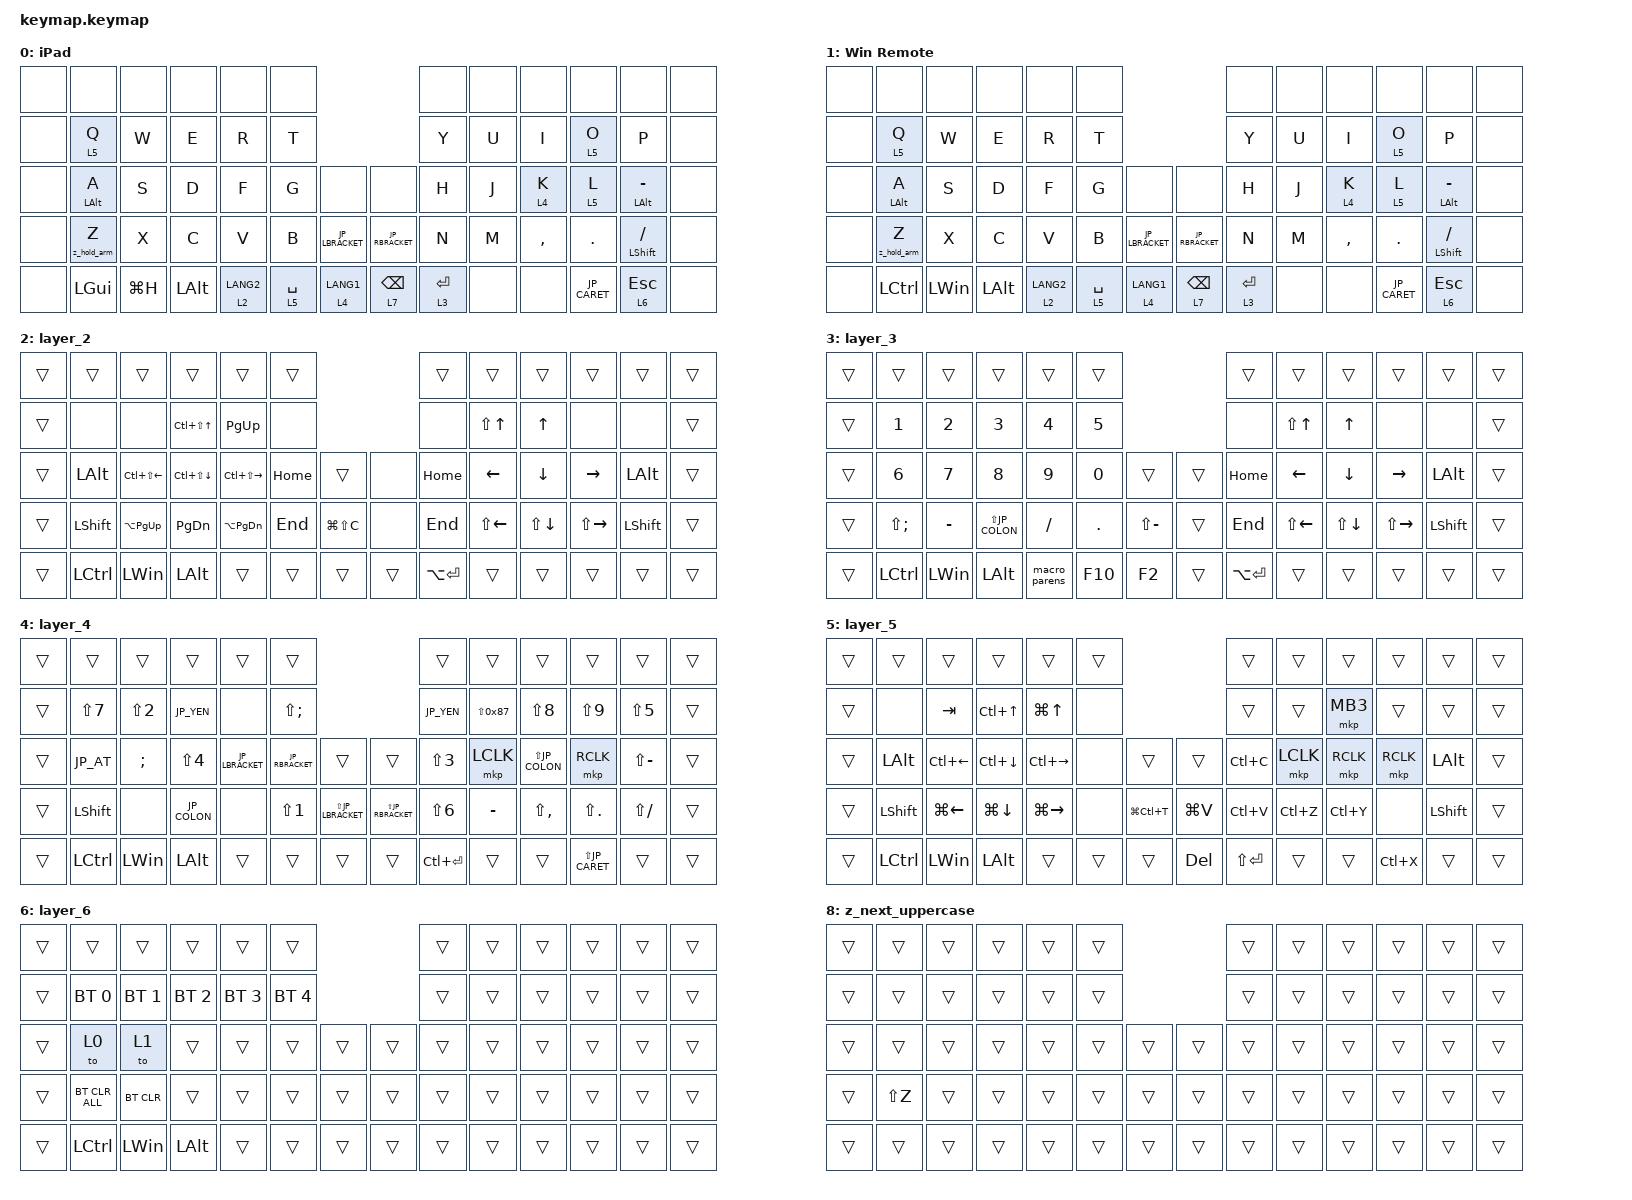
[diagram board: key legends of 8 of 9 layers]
#include <behaviors.dtsi>

&sl {
    release-after-ms = <300>;
};
#include <dt-bindings/zmk/bt.h>
#include <dt-bindings/zmk/keys.h>
#include <dt-bindings/zmk/outputs.h>
#include <dt-bindings/zmk/pointing.h>
#include <dt-bindings/zmk/input_transform.h>
#include <zephyr/dt-bindings/input/input-event-codes.h>
#include <scroll-snap.dtsi>

&mt {
    flavor = "balanced";
    quick-tap-ms = <0>;
};

// -------------------------------------------------------------------------
// JIS変換定義 (OSが日本語配列設定の場合の出力マッピング)
// -------------------------------------------------------------------------
#define JP_AT           LBKT             // @ (USの [ キー)
#define JP_CARET        EQUAL            // ^ (USの = キー)
#define JP_YEN          INT3             // ¥ (JISの ¥ キー)
#define JP_PIPE         LS(INT3)         // | (Shift + ¥)
#define JP_COLON        SQT              // : (USの ' キー)
#define JP_LBRACKET     RBKT             // [ (USの ] キー)
#define JP_RBRACKET     NUHS             // ] (USの \ キー / Non-US #)
#define JP_UNDERSCORE   LS(INT1)         // _ (Shift + Ro)
#define JP_BACKSLASH    INT1             // \ (Roキー)

// Shiftが必要な記号
#define JP_DQUOTE       LS(N2)           // "
#define JP_AMPERSAND    LS(N6)           // &
#define JP_QUOTE        LS(N7)           // '
#define JP_LPAREN       LS(N8)           // (
#define JP_RPAREN       LS(N9)           // )
#define JP_EQUAL        LS(MINUS)        // =
#define JP_PLUS         LS(SEMI)         // +
#define JP_ASTERISK     LS(SQT)          // *
#define JP_TILD         LS(EQUAL)        // ~
#define JP_GRAVE        LS(LBKT)         // `
#define JP_LBRACE       LS(RBKT)         // {
#define JP_RBRACE       LS(NUHS)         // }

/ {
    macros {
        // roBaと同じ: 長押し中はShift、離した直後だけ次のZを大文字にする。
        z_hold_arm: z_hold_arm {
            compatible = "zmk,behavior-macro";
            #binding-cells = <0>;
            wait-ms = <0>;
            tap-ms = <10>;
            bindings =
                <&macro_press &kp LSHFT>
                , <&macro_pause_for_release>
                , <&macro_release &kp LSHFT>
                , <&macro_tap &sl 8>;
        };

        // enダッシュ (Alt + 0150)
        en_dash: en_dash {
            compatible = "zmk,behavior-macro";
            #binding-cells = <0>;
            bindings
                = <&macro_press &kp LALT>
                , <&macro_tap &kp KP_N0 &kp KP_N1 &kp KP_N5 &kp KP_N0>
                , <&macro_release &kp LALT>;
        };

        // emダッシュ (Alt + 0151)
        em_dash: em_dash {
            compatible = "zmk,behavior-macro";
            #binding-cells = <0>;
            bindings
                = <&macro_press &kp LALT>
                , <&macro_tap &kp KP_N0 &kp KP_N1 &kp KP_N5 &kp KP_N1>
                , <&macro_release &kp LALT>;
        };

        // 数学マイナス記号 (Alt + 8722)
        math_minus: math_minus {
            compatible = "zmk,behavior-macro";
            #binding-cells = <0>;
            bindings
                = <&macro_press &kp LALT>
                , <&macro_tap &kp KP_N8 &kp KP_N7 &kp KP_N2 &kp KP_N2>
                , <&macro_release &kp LALT>;
        };
        
        macro_parens: macro_parens {
            compatible = "zmk,behavior-macro";
            #binding-cells = <0>;
            wait-ms = <20>; // キー入力間の待機時間
            tap-ms = <20>;  // キーを押している時間
            bindings
                = <&kp LS(N8)>    // 「(」を入力
                , <&kp LS(N9)>    // 「)」を入力
                , <&kp LEFT>;  // 左矢印「←」を入力してカーソルを戻す
        };

        // 単発・ホールド兼用のミドルクリックマクロ
        mclk_macro_hold: mclk_macro_hold {
            compatible = "zmk,behavior-macro";
            #binding-cells = <0>;
            wait-ms = <0>;
            tap-ms = <0>;
            bindings = <&macro_press &mkp MB3>
                     , <&macro_pause_for_release>
                     , <&macro_release &mkp MB3>;
        };

        // Ctrl＋ミドルクリックのホールド用マクロ
        ctrl_mclk_macro_hold: ctrl_mclk_macro_hold {
            compatible = "zmk,behavior-macro";
            #binding-cells = <0>;
            wait-ms = <0>;
            tap-ms = <0>;
            bindings = <&macro_press &kp LCTRL &mkp MB3>
                     , <&macro_pause_for_release>
                     , <&macro_release &kp LCTRL &mkp MB3>;
        };
    };

    behaviors {
        // Z: normal Japanese typing first; hold 170 ms = Shift.
        z_shift: z_shift {
            compatible = "zmk,behavior-hold-tap";
            label = "Z_SHIFT";
            #binding-cells = <2>;
            bindings = <&z_hold_arm>, <&kp>;
            flavor = "tap-preferred";
            tapping-term-ms = <170>;
            quick-tap-ms = <0>;
            require-prior-idle-ms = <125>;
        };

        // A: keep letter taps responsive, delay hold Alt to 320 ms.
        a_alt_slow: a_alt_slow {
            compatible = "zmk,behavior-hold-tap";
            #binding-cells = <2>;
            bindings = <&kp>, <&kp>;
            flavor = "tap-preferred";
            tapping-term-ms = <320>;
            quick-tap-ms = <150>;
            require-prior-idle-ms = <125>;
        };

        // 右Shift専用: 左Zと同じ170ms。通常のスラッシュ入力はタップ優先。
        slash_shift_fast: slash_shift_fast {
            compatible = "zmk,behavior-hold-tap";
            #binding-cells = <2>;
            bindings = <&kp>, <&kp>;
            flavor = "tap-preferred";
            tapping-term-ms = <170>;
            quick-tap-ms = <0>;
            require-prior-idle-ms = <125>;
        };

        // 高速タイピング用のMod-Tap設定（Home Row Mods用）
        mt_tap: mod_tap_preferred {
            compatible = "zmk,behavior-hold-tap";
            #binding-cells = <2>;
            flavor = "tap-preferred";      // ★重要：他のキーと重なってもTap（文字）を優先する
            tapping-term-ms = <200>;       // 長押しの判定時間（好みで調整）
            quick-tap-ms = <150>;          // 連続タップで文字をリピートさせる
            require-prior-idle-ms = <125>; // ★超重要：直前に別のキーを打っていたら、強制的にTapにする
            bindings = <&kp>, <&kp>;
        };
        
        // KとL専用の遅いLayer-Tap
        lt_slow: layer_tap_slow {
            compatible = "zmk,behavior-hold-tap";
            #binding-cells = <2>;
            flavor = "tap-preferred"; // 短く押した時は確実にキー入力を優先
            tapping-term-ms = <250>;  // ★ここを好みの長さに設定（デフォルトは200）
            quick-tap-ms = <200>;     // 連続タップ時のレイヤー暴発防止
            require-prior-idle-ms = <125>; // ★これを追加：直前に別のキー入力があれば絶対にTap(文字)にする
            bindings = <&mo>, <&kp>;  // 長押しでレイヤー(&mo)、短押しでキー(&kp)
            
            display-name = "Layer Tap Slow";
        };

        // ダブルタップ＆ホールドで連続バックスペースになるLayer-Tap
        lt_bspc: layer_tap_backspace {
            compatible = "zmk,behavior-hold-tap";
            #binding-cells = <2>;
            flavor = "tap-preferred";
            tapping-term-ms = <200>; // 通常の長押し（Hold）判定時間
            quick-tap-ms = <200>;    // ★ここがダブルタップリピートの受付時間です
            bindings = <&mo>, <&kp>; // ※もしMod-Tapとして使う場合は <&kp>, <&kp> にしてください
        };

        // ① カンマ用：ホールドでMB3、タップで通常のキー（bindingsを同一種にするためマクロでラップ）
        p_mt_mb3: p_mt_mb3 {
            compatible = "zmk,behavior-hold-tap";
            #binding-cells = <2>;
            flavor = "tap-preferred";
            tapping-term-ms = <200>;
            quick-tap-ms = <150>;
            require-prior-idle-ms = <125>;
            bindings = <&mclk_macro_hold>, <&kp>; // 両方とも「マクロ」として扱うことでエラーを回避
        };

        // ② ドット用：ホールドでCtrl+MB3、タップで通常のキー
        p_mt_ctrl_mb3: p_mt_ctrl_mb3 {
            compatible = "zmk,behavior-hold-tap";
            #binding-cells = <2>;
            flavor = "tap-preferred";
            tapping-term-ms = <200>;
            quick-tap-ms = <150>;
            require-prior-idle-ms = <125>;
            bindings = <&ctrl_mclk_macro_hold>, <&kp>; // 両方とも「マクロ」として扱う
        };
    };

    keymap {
        compatible = "zmk,keymap";

        mac_ipad {
            display-name = "iPad";
            bindings = <
&none      &none             &none         &none         &none       &none                                                      &none        &none  &none               &none                &none                &none
&none      &lt_slow 5 Q      &kp W         &kp E         &kp R       &kp T                                                      &kp Y        &kp U  &kp I               &lt_slow 5 O         &kp P                &none
&none      &a_alt_slow LALT A    &kp S         &kp D         &kp F       &kp G        &none                      &none              &kp H        &kp J  &lt_slow 4 K        &lt_slow 5 L         &a_alt_slow LALT MINUS   &none
&none      &z_shift 0 Z   &kp X         &kp C         &kp V       &kp B        &kp JP_LBRACKET            &kp JP_RBRACKET    &kp N        &kp M  &kp COMMA           &kp DOT              &slash_shift_fast LSHFT SLASH  &none
&none      &kp LGUI          &kp LG(H)      &kp LEFT_ALT  &lt 2 LANG2  &lt 5 SPACE  &lt 4 LANG1                 &lt_bspc 7 BSPC    &lt 3 RET    &none  &none               &kp JP_CARET         &lt 6 ESC            &none
            >;
        };

        win_remote {
            display-name = "Win Remote";
            bindings = <
&none      &none             &none         &none         &none       &none                                                      &none        &none  &none               &none                &none                &none
&none      &lt_slow 5 Q      &kp W         &kp E         &kp R       &kp T                                                      &kp Y        &kp U  &kp I               &lt_slow 5 O         &kp P                &none
&none      &a_alt_slow LALT A    &kp S         &kp D         &kp F       &kp G        &none                      &none              &kp H        &kp J  &lt_slow 4 K        &lt_slow 5 L         &a_alt_slow LALT MINUS   &none
&none      &z_shift 0 Z   &kp X         &kp C         &kp V       &kp B        &kp JP_LBRACKET            &kp JP_RBRACKET    &kp N        &kp M  &kp COMMA           &kp DOT              &slash_shift_fast LSHFT SLASH  &none
&none      &kp LCTRL         &kp LWIN      &kp LEFT_ALT  &lt 2 LANG2  &lt 5 SPACE  &lt 4 LANG1                 &lt_bspc 7 BSPC    &lt 3 RET    &none  &none               &kp JP_CARET         &lt 6 ESC            &none
            >;
        };

        layer_2 {
            bindings = <
&trans  &trans     &trans               &trans            &trans              &trans                            &trans          &trans           &trans            &trans         &trans    &trans
&trans  &none      &none                &kp LC(LS(UP))    &kp PG_UP           &none                             &none           &kp LS(UP)       &kp UP            &none          &none     &trans
&trans  &kp LALT   &kp LC(LS(LEFT))     &kp LC(LS(DOWN))  &kp LC(LS(RIGHT))   &kp HOME   &trans         &none   &kp HOME        &kp LEFT         &kp DOWN          &kp RIGHT      &kp LALT  &trans
&trans  &kp LSHFT  &kp LA(PG_UP)        &kp PG_DN         &kp LA(PG_DN)       &kp END    &kp LG(LS(C))  &none   &kp END         &kp LS(LEFT)     &kp LS(DOWN)      &kp LS(RIGHT)  &kp LSHFT &trans
&trans  &kp LCTRL  &kp LWIN             &kp LALT          &trans              &trans     &trans         &trans  &kp LA(ENTER)   &trans           &trans            &trans         &trans    &trans
            >;
        };

        layer_3 {
            bindings = <
&trans  &trans       &trans      &trans           &trans        &trans                          &trans        &trans           &trans            &trans         &trans       &trans
&trans  &kp N1       &kp N2      &kp N3           &kp N4        &kp N5                          &none         &kp LS(UP)       &kp UP            &none          &none        &trans
&trans  &kp N6       &kp N7      &kp N8           &kp N9        &kp N0   &trans         &trans  &kp HOME      &kp LEFT         &kp DOWN          &kp RIGHT      &kp LALT     &trans
&trans  &kp LS(SEMI) &kp MINUS   &kp LS(JP_COLON) &kp FSLH      &kp DOT  &kp LS(MINUS)  &trans  &kp END       &kp LS(LEFT)     &kp LS(DOWN)      &kp LS(RIGHT)  &kp LSHFT    &trans
&trans  &kp LCTRL    &kp LWIN    &kp LALT         &macro_parens &kp F10  &kp F2         &trans  &kp LA(ENTER) &trans           &trans            &trans         &trans       &trans
            >;
        };

        layer_4 {
            bindings = <
&trans  &trans        &trans        &trans        &trans          &trans                                                     &trans        &trans       &trans           &trans            &trans         &trans
&trans  &kp LS(N7)    &kp LS(N2)    &kp JP_YEN    &none           &kp LS(SEMI)                                               &kp JP_YEN    &kp LS(0x87) &kp LS(N8)       &kp LS(N9)        &kp LS(N5)     &trans
&trans  &kp JP_AT     &kp SEMI      &kp LS(N4)    &kp JP_LBRACKET &kp JP_RBRACKET  &trans               &trans               &kp LS(N3)    &mkp LCLK    &kp LS(JP_COLON) &mkp RCLK         &kp LS(MINUS)  &trans
&trans  &kp LSHFT     &none         &kp JP_COLON  &none           &kp LS(N1)       &kp LS(JP_LBRACKET)  &kp LS(JP_RBRACKET)  &kp LS(N6)    &kp MINUS    &kp LS(COMMA)    &kp LS(DOT)       &kp LS(FSLH)   &trans
&trans  &kp LCTRL     &kp LWIN      &kp LALT      &trans          &trans           &trans               &trans               &kp LC(ENTER) &trans       &trans           &kp LS(JP_CARET)  &trans         &trans
            >;
        };

        layer_5 {
            bindings = <
&trans  &trans     &trans         &trans         &trans         &trans                             &trans        &trans     &trans      &trans       &trans      &trans
&trans  &none      &kp TAB        &kp LC(UP)     &kp LG(UP)     &none                              &trans        &trans     &mkp MB3     &trans       &trans      &trans
&trans  &kp LALT   &kp LC(LEFT)   &kp LC(DOWN)   &kp LC(RIGHT)  &none    &trans         &trans     &kp LC(C)     &mkp LCLK  &mkp RCLK   &mkp RCLK    &kp LALT    &trans
&trans  &kp LSHFT  &kp LG(LEFT)   &kp LG(DOWN)   &kp LG(RIGHT)  &none    &kp LG(LC(T))  &kp LG(V)  &kp LC(V)     &kp LC(Z)  &kp LC(Y)   &none        &kp LSHFT   &trans
&trans  &kp LCTRL  &kp LWIN       &kp LALT       &trans         &trans   &trans         &kp DEL    &kp LS(ENTER) &trans     &trans      &kp LC(X)    &trans      &trans
            >;
        };

        layer_6 {
            bindings = <
&trans  &trans          &trans        &trans        &trans          &trans                            &trans  &trans  &trans  &trans  &trans  &trans
&trans  &bt BT_SEL 0    &bt BT_SEL 1  &bt BT_SEL 2  &bt BT_SEL 3    &bt BT_SEL 4                      &trans  &trans  &trans  &trans  &trans  &trans
&trans  &to 0           &to 1        &trans        &trans          &trans        &trans      &trans  &trans  &trans  &trans  &trans  &trans  &trans
&trans  &bt BT_CLR_ALL  &bt BT_CLR    &trans        &trans          &trans        &trans      &trans  &trans  &trans  &trans  &trans  &trans  &trans
&trans  &kp LCTRL       &kp LWIN      &kp LALT      &trans          &trans        &trans      &trans  &trans  &trans  &trans  &trans  &trans  &trans
            >;
        };

        layer_7 {
            bindings = <
&trans  &trans     &trans    &trans       &trans    &trans                                  &trans  &trans  &trans  &trans  &trans    &trans
&trans  &kp F1     &kp F2    &kp F3       &kp F4    &kp F5                                  &trans  &trans  &trans  &trans  &trans    &trans
&trans  &kp F6     &kp F7    &kp F8       &kp F9    &kp F10  &trans     &trans      &trans  &trans  &trans  &trans  &trans  &kp LALT  &trans
&trans  &kp F11    &kp F12   &trans       &trans    &trans   &trans     &trans      &trans  &trans  &trans  &trans  &trans  &kp LSHFT &trans
&trans  &kp LCTRL  &kp LWIN  &kp LALT     &kp TAB   &kp RET  &kp BSPC   &trans      &trans  &trans  &trans  &trans  &trans  &trans    &trans
            >;
        };

        z_next_uppercase {
            bindings = <
&trans &trans &trans &trans &trans &trans &trans &trans &trans &trans &trans &trans
&trans &trans &trans &trans &trans &trans &trans &trans &trans &trans &trans &trans
&trans &trans &trans &trans &trans &trans &trans &trans &trans &trans &trans &trans &trans &trans
&trans &kp LS(Z) &trans &trans &trans &trans &trans &trans &trans &trans &trans &trans &trans &trans
&trans &trans &trans &trans &trans &trans &trans &trans &trans &trans &trans &trans &trans &trans
            >;
        };
    };
};

/ {
    // roBaと同様、横スクロール成分だけ50%にする。
    // 縦方向と全体倍率1/4は変更しない。
    torabo_horizontal_scroll_scaler: torabo_horizontal_scroll_scaler {
        compatible = "zmk,input-processor-scaler";
        #input-processor-cells = <2>;
        type = <INPUT_EV_REL>;
        codes = <INPUT_REL_HWHEEL>;
        track-remainders;


    };
};

// roBa と同じ方向固定。縦横どちらかに判定して斜め入力を抑える。
&zip_scroll_snap {
    x-threshold = <1 1>;
    y-threshold = <1 1>;
    require-n-samples = <4>;
    lock-duration-ms = <200>;
    lock-for-next-n-events = <8>;
    idle-reset-timeout-ms = <180>;
};

/ {
    // フリック開始・減速は縦横共通。toraboの既存スクロール倍率 (1/4) と整合。
    torabo_scroll_inertia: torabo_scroll_inertia {
        compatible = "zmk,input-processor-scroll-inertia";
        status = "disabled"; // 周辺ビルドではコンパイルしない（中央のみ有効化）
        #input-processor-cells = <0>;
        axis = <0>;
        layer = <4>;
        scale = <1>;
        scale-div = <4>;
        start = <20>;
        move = <10>;
        min-events = <3>;
        decay-fast = <990>;
        friction = <25>;
        stop = <2>;
    };
};

&pointing_listener {
    /* 通常時のトラックボール操作速度（ポインタ移動速度）を調整 */
input-processors = <&zip_xy_transform (INPUT_TRANSFORM_X_INVERT | INPUT_TRANSFORM_Y_INVERT)>, <&zip_xy_scaler 2 5>;

    scroller {
        layers = <4>;
        /* スクロール速度を調整（例：感度を半分の 1/4 に落とす） */
        input-processors = <&zip_xy_transform (INPUT_TRANSFORM_X_INVERT)>, <&zip_xy_to_scroll_mapper>, <&zip_scroll_snap>, <&torabo_horizontal_scroll_scaler 1 2>, <&torabo_scroll_inertia>, <&zip_scroll_scaler 1 4>;
    };
};
